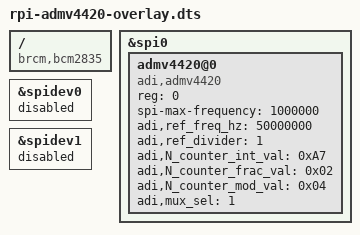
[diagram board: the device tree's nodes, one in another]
/dts-v1/;
/plugin/;
/ {
	compatible = "brcm,bcm2835", "brcm,bcm2708", "brcm,bcm2709";

	fragment@0 {
		target = <&spi0>;
		__overlay__ {
			#address-cells = <1>;
			#size-cells = <0>;
			status = "okay";

			admv4420@0 {
				compatible = "adi,admv4420";
				reg = <0>;
				spi-max-frequency = <1000000>;

				/* reference block config */
				adi,ref_freq_hz = <50000000>;
				// adi,ref_single_ended_en;
				// adi,ref_doubler_en;
				// adi,ref_divide_by_2_en;
				adi,ref_divider = <1>;

				/* N counter config*/
				adi,N_counter_int_val = <0xA7>;
				adi,N_counter_frac_val = <0x02>;
				adi,N_counter_mod_val = <0x04>;

				adi,mux_sel = <1>;
			};
		};
	};

	fragment@1 {
		target = <&spidev0>;
		__overlay__ {
			status = "disabled";
		};
	};

	fragment@2 {
		target = <&spidev1>;
		__overlay__ {
			status = "disabled";
		};
	};
};
